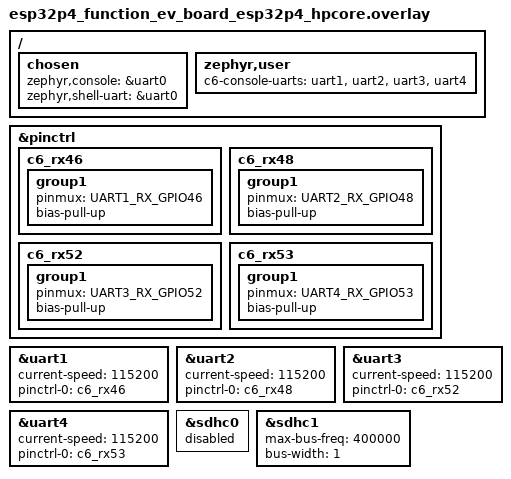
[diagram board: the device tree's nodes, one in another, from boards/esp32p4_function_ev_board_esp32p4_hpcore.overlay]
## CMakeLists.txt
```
# SPDX-License-Identifier: GPL-3.0-or-later

cmake_minimum_required(VERSION 3.20.0)

find_package(Zephyr REQUIRED HINTS $ENV{ZEPHYR_BASE})
project(esp_sdr_c6_bootstrap)

# The ESP32-C6 image to install: zephyr/zephyr.bin of a build for the C6 with
# CONFIG_ESP_IDF_BOOTLOADER (apps/osmosdr_serial for esp32p4_function_ev_board/esp32c6/hpcore).
# Without one the app only reports the C6's firmware version.
set(C6_IMAGE "" CACHE FILEPATH "ESP32-C6 application image to install")

target_sources(app PRIVATE src/main.c)
if(C6_IMAGE)
  if(NOT EXISTS "${C6_IMAGE}")
    message(FATAL_ERROR "C6_IMAGE '${C6_IMAGE}' does not exist")
  endif()
  target_compile_definitions(app PRIVATE C6_IMAGE_BUILT_IN=1)
  generate_inc_file_for_target(app ${C6_IMAGE}
    ${ZEPHYR_BINARY_DIR}/include/generated/c6_image.inc)
endif()
```

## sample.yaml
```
sample:
  name: ESP-SDR ESP32-C6 bootstrap
  description: >-
    The ESP32-P4-Function-EV-Board's ESP32-P4 installs an ESP32-C6 image through the C6's
    esp-hosted-mcu firmware (its OTA requests over SDIO)
common:
  tags: esp-sdr
  platform_allow:
    - esp32p4_function_ev_board/esp32p4/hpcore
tests:
  esp_sdr.c6_bootstrap:
    build_only: true
```

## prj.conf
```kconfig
# SPDX-License-Identifier: GPL-3.0-or-later
#
# The ESP32-P4 installs an image on its ESP32-C6 through the C6's esp-hosted-mcu firmware.

CONFIG_ESP_HOSTED_MCU=y
CONFIG_LOG=y
CONFIG_MAIN_STACK_SIZE=4096
```

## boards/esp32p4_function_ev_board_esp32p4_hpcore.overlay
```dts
/*
 * SPDX-License-Identifier: GPL-3.0-or-later
 *
 * The ESP32-C6's ESP-Prog connector (CHIP_PU, U0TXD, U0RXD, GPIO9) wired to ESP32-P4 GPIO46,
 * 48, 52 and 53, which of them to which unknown: a receiver on each shows which one carries the
 * C6's console (its ROM, its bootloader, the installed image).
 */

#include <zephyr/dt-bindings/pinctrl/esp32p4-pinctrl.h>

/ {
	/* Early boards (V1.0B, v1.4) have a USB-UART on UART0, no USB-Serial-JTAG connector. */
	chosen {
		zephyr,console = &uart0;
		zephyr,shell-uart = &uart0;
	};

	zephyr,user {
		c6-console-uarts = <&uart1 &uart2 &uart3 &uart4>;
	};
};

&pinctrl {
	c6_rx46: c6_rx46 {
		group1 {
			pinmux = <UART1_RX_GPIO46>;
			bias-pull-up;
		};
	};

	c6_rx48: c6_rx48 {
		group1 {
			pinmux = <UART2_RX_GPIO48>;
			bias-pull-up;
		};
	};

	c6_rx52: c6_rx52 {
		group1 {
			pinmux = <UART3_RX_GPIO52>;
			bias-pull-up;
		};
	};

	c6_rx53: c6_rx53 {
		group1 {
			pinmux = <UART4_RX_GPIO53>;
			bias-pull-up;
		};
	};
};

&uart1 {
	status = "okay";
	current-speed = <115200>;
	pinctrl-0 = <&c6_rx46>;
	pinctrl-names = "default";
};

&uart2 {
	status = "okay";
	current-speed = <115200>;
	pinctrl-0 = <&c6_rx48>;
	pinctrl-names = "default";
};

&uart3 {
	status = "okay";
	current-speed = <115200>;
	pinctrl-0 = <&c6_rx52>;
	pinctrl-names = "default";
};

&uart4 {
	status = "okay";
	current-speed = <115200>;
	pinctrl-0 = <&c6_rx53>;
	pinctrl-names = "default";
};

/* Only the C6's slot: the microSD slot shares the controller. */
&sdhc0 {
	status = "disabled";
};

/* Revision v0.0 P4s time out changing the card clock after initialization. */
&sdhc1 {
	max-bus-freq = <400000>;
	bus-width = <1>;
};
```

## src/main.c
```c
/*
 * SPDX-License-Identifier: GPL-3.0-or-later
 *
 * The ESP32-P4 installs an ESP32-C6 image through the C6's esp-hosted-mcu firmware, as the
 * EV board's C6 ships: the image (built in, C6_IMAGE) goes to the C6's next OTA partition by
 * the firmware's OTA requests over SDIO. Firmware before v2.6.0 selects the new partition and
 * restarts on its own after the end request, later firmware on the activate request. From then
 * on the C6 runs the image (apps/osmosdr_serial with CONFIG_APP_LINK_SDIO), and updates go
 * over its own SDIO link.
 */

#include <errno.h>
#include <string.h>

#include <zephyr/device.h>
#include <zephyr/devicetree.h>
#include <zephyr/drivers/uart.h>
#include <zephyr/kernel.h>
#include <zephyr/logging/log.h>
#include <zephyr/sys/byteorder.h>

#include <esp_hosted_mcu.h>

LOG_MODULE_REGISTER(c6_bootstrap, LOG_LEVEL_INF);

#if defined(C6_IMAGE_BUILT_IN)
static const uint8_t image[] = {
#include "c6_image.inc"
};
#else
static const uint8_t image[1];
#endif

/* esp_image_header_t: magic at 0, chip id (13 = ESP32-C6) at 12; the descriptor at 0x20 */
#define IMAGE_MAGIC 0xe9U
#define IMAGE_CHIP_ID_OFFSET 12U
#define IMAGE_CHIP_ID_ESP32C6 13U
#define APP_DESC_OFFSET 0x20U
#define APP_DESC_MAGIC 0xabcd5432U

#define FW_VERSION_ACTIVATE ESP_HOSTED_MCU_FW_VERSION_VAL(2, 6, 0)

/*
 * The C6's console, where the board wires it to this chip (zephyr,user c6-console-uarts: a
 * receiver per candidate pin): logged a line at a time, to see the C6 restart into the image.
 */
#define USER_NODE DT_PATH(zephyr_user)

#if DT_NODE_HAS_PROP(USER_NODE, c6_console_uarts)
#define CONSOLE_UART(node, prop, idx) DEVICE_DT_GET(DT_PHANDLE_BY_IDX(node, prop, idx)),
static const struct device *const console[] = {
	DT_FOREACH_PROP_ELEM(USER_NODE, c6_console_uarts, CONSOLE_UART)};

static void console_fn(void *p1, void *p2, void *p3)
{
	static char line[ARRAY_SIZE(console)][128];
	static size_t len[ARRAY_SIZE(console)];

	ARG_UNUSED(p1);
	ARG_UNUSED(p2);
	ARG_UNUSED(p3);
	for (;;) {
		bool idle = true;

		for (size_t i = 0; i < ARRAY_SIZE(console); i++) {
			unsigned char c;

			while (uart_poll_in(console[i], &c) == 0) {
				idle = false;
				if (c == '\n' || len[i] == sizeof(line[i]) - 1U) {
					line[i][len[i]] = '\0';
					LOG_INF("C6 (%s): %s", console[i]->name, line[i]);
					len[i] = 0;
				} else if (c != '\r') {
					line[i][len[i]++] = (char)c;
				}
			}
		}
		if (idle) {
			k_msleep(1);
		}
	}
}

K_THREAD_DEFINE(console_thread, 2048, console_fn, NULL, NULL, NULL, 5, 0, 0);
#endif

static int check_image(void)
{
	if (sizeof(image) < APP_DESC_OFFSET + sizeof(uint32_t) || image[0] != IMAGE_MAGIC) {
		LOG_ERR("not an ESP image");
		return -EINVAL;
	}
	if (sys_get_le16(&image[IMAGE_CHIP_ID_OFFSET]) != IMAGE_CHIP_ID_ESP32C6) {
		LOG_ERR("image is not for the ESP32-C6 (chip id %u)",
			sys_get_le16(&image[IMAGE_CHIP_ID_OFFSET]));
		return -EINVAL;
	}
	if (sys_get_le32(&image[APP_DESC_OFFSET]) != APP_DESC_MAGIC) {
		LOG_ERR("image has no application descriptor (CONFIG_ESP_IDF_BOOTLOADER)");
		return -EINVAL;
	}
	return 0;
}

int main(void)
{
	const struct device *hosted = DEVICE_DT_GET(DT_NODELABEL(esp_hosted_mcu));
	uint32_t version = esp_hosted_mcu_fw_version();
	size_t done = 0;
	int ret;

	if (!device_is_ready(hosted)) {
		LOG_ERR("esp-hosted-mcu link is down (is the C6 running esp-hosted-mcu?)");
		return 0;
	}

	LOG_INF("C6 firmware v%u.%u.%u", ESP_HOSTED_MCU_FW_VERSION_MAJOR(version),
		ESP_HOSTED_MCU_FW_VERSION_MINOR(version), ESP_HOSTED_MCU_FW_VERSION_PATCH(version));

	if (!IS_ENABLED(C6_IMAGE_BUILT_IN)) {
		LOG_INF("no image built in (C6_IMAGE)");
		return 0;
	}
	if (check_image() != 0) {
		return 0;
	}

	LOG_INF("installing %zu bytes", sizeof(image));

	ret = esp_hosted_mcu_ota_begin();
	if (ret != 0) {
		LOG_ERR("OTA begin: %d", ret);
		return 0;
	}

	while (done < sizeof(image)) {
		size_t len = MIN(sizeof(image) - done, ESP_HOSTED_MCU_OTA_CHUNK_SIZE);

		ret = esp_hosted_mcu_ota_write(&image[done], len);
		if (ret != 0) {
			LOG_ERR("OTA write at %zu: %d", done, ret);
			return 0;
		}
		done += len;
		if ((done / ESP_HOSTED_MCU_OTA_CHUNK_SIZE) % 64 == 0 || done == sizeof(image)) {
			LOG_INF("%zu/%zu", done, sizeof(image));
		}
	}

	ret = esp_hosted_mcu_ota_end();
	if (ret != 0) {
		LOG_ERR("OTA end: %d (image rejected by the C6)", ret);
		return 0;
	}

	if (version >= FW_VERSION_ACTIVATE) {
		ret = esp_hosted_mcu_ota_activate();
		if (ret != 0) {
			LOG_ERR("OTA activate: %d", ret);
			return 0;
		}
	}

	LOG_INF("installed; the C6 restarts into it within seconds");
	return 0;
}
```
